# WE2_S_NS register map
Vendor: ARM Ltd.; Series: ARMv8.1-M Mainline; File version: 1.0
CPU: CM55 r1p1, little endian, MPU, FPU, double-precision FPU, DSP, VTOR, 3 interrupt priority bits
Registers are 32-bit, read-write, reset 0x0 unless marked. A register's access mark holds for its fields unless they carry their own. Offsets are from the block's base; [hi:lo] are bit positions.

## SYS_FPU — Floating-Point Context Control Register
Base 0xE000EF30
Same registers: SYS_FPU_NS 0xE002EF30
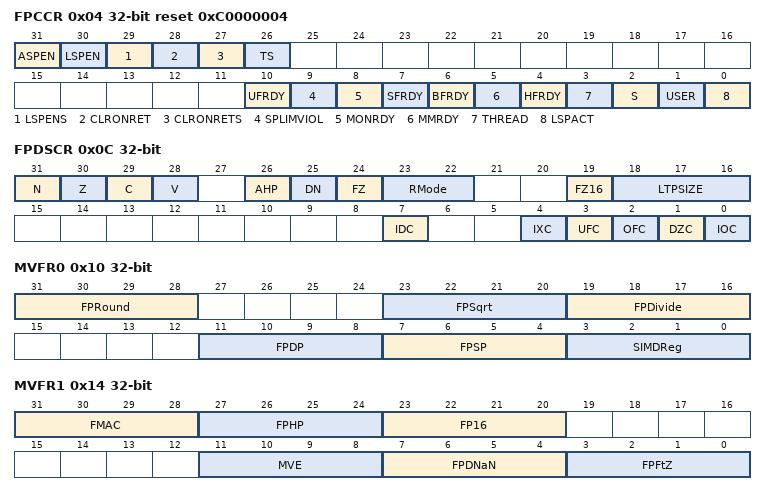
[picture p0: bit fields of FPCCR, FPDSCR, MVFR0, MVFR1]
0x04 FPCCR reset 0xC0000004 — Floating-point Context Control Register
  [31] ASPEN — Automatic state preservation enable. Enables CONTROL.FPCA setting on execution of a floating-point instruction. This results in automatic hardware state preservation and restoration, for floating-point context, on exception entry and exit. The possible values of this bit are: [0] Disable CONTROL.FPCA setting on execution of a floating-point instruction. [1] Enable CONTROL.FPCA setting on execution of a floating-point instruction.
  [30] LSPEN — Automatic state preservation enable. Enables lazy context save of floating-point state. The possible values of this bit are: [0] Disable automatic lazy context save. [1] Enable automatic lazy state preservation for floating-point context.
  [29] LSPENS — RAZ/WI.
  [28] CLRONRET — Clear on return. Clear floating-point caller saved registers on exception return. The possible values of this bit are: [0] Disabled. [1] Enabled.
  [27] CLRONRETS — RAZ/WI.
  [26] TS — RAZ/WI.
  [10] UFRDY — UsageFault ready. Indicates whether the software executing when the processor allocated the floating-point stack frame was able to set the UsageFault exception to pending. The possible values of this bit are: [0] Not able to set the UsageFault exception to pending. [1] Able to set the UsageFault exception to pending.
  [9] SPLIMVIOL — Stack pointer limit violation. This bit indicates whether the floating-point context violates the stack pointer limit that was active when lazy state preservation was activated. SPLIMVIOL modifies the lazy floatingpoint state preservation behavior. The possible values of this bit are: [0] The existing behavior is retained. [1] The memory accesses associated with the floating-point state preservation are not performed.
  [8] MONRDY — DebugMonitor ready. Indicates whether the software executing when the processor allocated the floatingpoint stack frame was able to set the DebugMonitor exception to pending. The possible values of this bit are: [0] Not able to set the DebugMonitor exception to pending. [1] Able to set the DebugMonitor exception to pending.
  [7] SFRDY — RAZ/WI.
  [6] BFRDY — BusFault ready. Indicates whether the software executing when the processor allocated the floating-point stack frame was able to set the BusFault exception to pending. The possible values of this bit are: 0 Not able to set the BusFault exception to pending. 1 Able to set the BusFault exception to pending.
  [5] MMRDY — MemManage ready. Indicates whether the software executing when the processor allocated the floating-point stack frame was able to set the MemManage exception to pending. The possible values of this bit are: 0 Not able to set the MemManage exception to pending. 1 Able to set the MemManage exception to pending.
  [4] HFRDY — HardFault ready. Indicates whether the software executing when the processor allocated the floating-point stack frame was able to set the HardFault exception to pending. The possible values of this bit are: [0] Not able to set the HardFault exception to pending. [1] Able to set the HardFault exception to pending.
  [3] THREAD — Thread mode. Indicates the processor mode when it allocated the floating-point stack frame. The possible values of this bit are: [0] Handler mode. [1] Thread mode.
  [2] S — RAZ/WI
  [1] USER — Indicates the privilege level of the software executing, when the processor allocated the floating point stack. The possible values of this bit are: [0] Privileged level. [1] Unprivileged level
  [0] LSPACT — Lazy state preservation active. Indicates whether lazy preservation of the floating-point state is active. The possible values of this bit are: [0] Lazy state preservation is not active. [1] Lazy state preservation is active.
0x08 FPCAR — Floating-point Context Address Register
  [31:3] ADDRESS — The location of the unpopulated floating-point register space that is allocated on an exception stack frame.
0x0C FPDSCR — Floating-point Default Status Control Register
  [31] N — Negative condition code flag
  [30] Z — Zero condition code flag
  [29] C — Carry condition code flag
  [28] V — Overflow condition code flag
  [26] AHP — Alternative half-precision control bit: [0] IEEE half-precision format selected. [1] Alternative half-precision format selected.
  [25] DN — Default NaN mode control bit: [0] NaN operands propagate through to the output of a floating-point operation. [1] Any operation involving one or more NaNs returns the Default NaN.
  [24] FZ — Flush-to-zero mode control bit: [0] Flush-to-zero mode disabled. Behavior of the floating-point system is fully compliant with the IEEE 754 standard. [1] Flush-to-zero mode enabled.
  [23:22] RMode — Rounding Mode control field. The encoding of this field is: [0b00] Round to Nearest (RN) mode. [0b01] Round towards Plus Infinity (RP) mode. [0b10] Round towards Minus Infinity (RM) mode. [0b11] Round towards Zero (RZ) mode.
  [19] FZ16 — Flush-to-zero mode control for single and double precision Floating-point. This bit determines whether denormal Floating-point values are treated as though they are zero. The possible values of this bit are: [0] Flush-to-zero mode disabled. Behavior of the Floating-point unit is fully compliant with the IEEE754 standard. [1] Flush-to-zero mode enabled.
  [18:16] LTPSIZE — The vector element size used when applying low-overhead-loop tail predication to vector instructions. The possible values of this field are: [0b000] 8 bits [0b001] 16 bits [0b010] 32 bits [0b011] 64 bits [0b100] Tail predication not applied.
  [7] IDC — Input Denormal cumulative exception bit.
  [4] IXC — Inexact cumulative exception bit.
  [3] UFC — Underflow cumulative exception bit.
  [2] OFC — Overflow cumulative exception bit.
  [1] DZC — Division by Zero cumulative exception bit.
  [0] IOC — Invalid Operation cumulative exception bit.
0x10 MVFR0 ro — Media and VFP Feature Register 0
  [31:28] FPRound — Floating-point rounding modes. The possible values are: [0b0000] Rounding modes are not supported. [0b0001] All rounding modes are supported.
  [23:20] FPSqrt — Floating-point square root. The possible values are: [0b0000] Floating-point square root not supported. [0b0001] Floating-point square root is supported.
  [19:16] FPDivide — Floating-point divide. The possible values are: [0b0000] Floating-point divide operations are not supported. [0b0001] Floating-point divide operations are supported.
  [11:8] FPDP — Floating-point double-precision. The possible values are: [0b0000] Floating-point double-precision operations are not supported. [0b0010] Floating-point double-precision operations are supported.
  [7:4] FPSP — Floating-point single-precision. The possible values are: [0b0000] Floating-point single-precision operations are not supported. [0b0010] Floating-point single-precision operations are supported.
  [3:0] SIMDReg — SIMD registers. The value of this field is 0b0001, indicating 16x64-bit registers.
0x14 MVFR1 ro — Media and VFP Feature Register 1
  [31:28] FMAC — Fused multiply accumulate instructions. The possible values are: [0b0000] Fused multiply accumulate instructions are not supported. [0b0001] Fused multiply accumulate instructions are supported.
  [27:24] FPHP — Floating-point half-precision conversion. The possible values are: [0b0000] Floating-point half-precision conversion instructions are not supported. [0b0001] Half-precision to single-precision is implemented. [0b0010] Half-precision to single and double-precision are implemented.
  [23:20] FP16 — Floating-point half-precision data processing. The possible values are: 0b0000 Floating-point half-precision data processing is not supported. 0b0001 Floating-point half-precision data processing is supported.
  [11:8] MVE — Indicates support for MVE. The possible values are: [0b0000] MVE is not supported. [0b0001] MVE is supported without Floating-point. [0b0010] MVE is supported with single and double-precision Floating-point.
  [7:4] FPDNaN — Floating-point default NaN. The possible values are: [0b0000] Floating-point default NaN propagation is not supported. [0b0001] Floating-point default NaN propagation is supported.
  [3:0] FPFtZ — Floating-point flush-to-zero. The possible values are: [0b0000] Floating-point flush-to-zero operations not supported. [0b0001] Full denormalized numbers arithmetic supported.
0x18 MVFR2 ro — Media and VFP Feature Register 2
  [7:4] FPMisc — Floating-point miscellaneous. Indicates support for miscellaneous FP features. The possible values are: [0b0000] Floating-point extensions not implemented. [0b0100] Selection, directed conversion to integer, VMINNM and MAXNM supported.
